# G32M3101 register map
File version: 1.0
CPU: CM0+ r0p1, little endian, MPU, no FPU, 2 interrupt priority bits
Registers are 32-bit, read-write, reset 0x0 unless marked. A register's access mark holds for its fields unless they carry their own. Offsets are from the block's base; [hi:lo] are bit positions; {n}, {i} and the like mark numbered series.

## GTMR — General purpose timer
Base 0x40001000
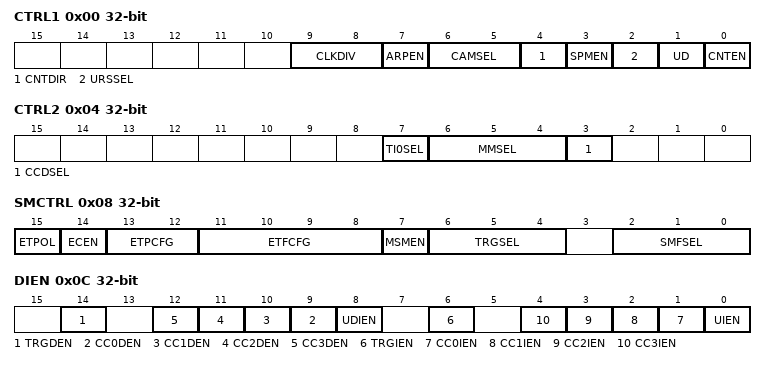
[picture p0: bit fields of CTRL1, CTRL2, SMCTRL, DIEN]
0x00 CTRL1 — control register 1
  [9:8] CLKDIV — Clock division
  [7] ARPEN — Auto-reload preload enable
  [6:5] CAMSEL — Center-aligned mode selection
  [4] CNTDIR — Direction
  [3] SPMEN — One-pulse mode
  [2] URSSEL — Update request source
  [1] UD — Update disable
  [0] CNTEN — Counter enable
0x04 CTRL2 — control register 2
  [7] TI0SEL — TI0 selection
  [6:4] MMSEL — Master mode selection
  [3] CCDSEL — Capture/compare DMA selection
0x08 SMCTRL — slave mode control register
  [15] ETPOL — External trigger polarity
  [14] ECEN — External clock enable
  [13:12] ETPCFG — External trigger prescaler
  [11:8] ETFCFG — External trigger filter
  [7] MSMEN — Master/Slave mode
  [6:4] TRGSEL — Trigger selection
  [2:0] SMFSEL — Slave mode selection
0x0C DIEN — DMA/Interrupt enable register
  [14] TRGDEN — Trigger DMA request enable
  [n+9] CC{n}DEN (n=0..3) — Capture/Compare {n} DMA request enable
  [8] UDIEN — Update DMA request enable
  [6] TRGIEN — Trigger interrupt enable
  [n+1] CC{n}IEN (n=0..3) — Capture/Compare {n} interrupt enable
  [0] UIEN — Update interrupt enable
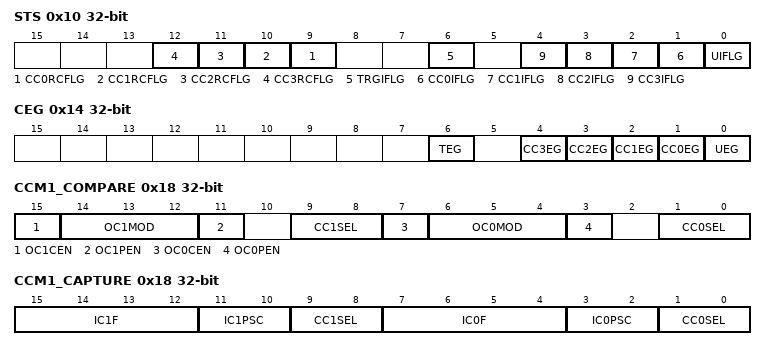
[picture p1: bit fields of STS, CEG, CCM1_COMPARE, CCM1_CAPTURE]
0x10 STS — status register
  [n+9] CC{n}RCFLG (n=0..3) — Capture/Compare {n} overcapture flag
  [6] TRGIFLG — Trigger interrupt flag
  [n+1] CC{n}IFLG (n=0..3) — Capture/compare {n} interrupt flag
  [0] UIFLG — Update interrupt flag
0x14 CEG wo — event generation register
  [6] TEG — Trigger generation
  [n+1] CC{n}EG (n=0..3) — Capture/compare {n} generation
  [0] UEG — Update generation
0x18 CCM1_COMPARE — capture/compare mode register 1 (output mode)
  [15] OC1CEN — Output Compare 1 clear enable
  [14:12] OC1MOD — Output Compare 1 mode
  [11] OC1PEN — Output Compare 1 preload enable
  [9:8] CC1SEL — Capture/Compare 1 selection
  [7] OC0CEN — Output Compare 0 clear enable
  [6:4] OC0MOD — Output Compare 0 mode
  [3] OC0PEN — Output Compare 0 preload enable
  [1:0] CC0SEL — Capture/Compare 0 selection
0x18 CCM1_CAPTURE (alternate view of CCM1_COMPARE) — capture/compare mode register 1 (input mode)
  [15:12] IC1F — Input capture 1 filter
  [11:10] IC1PSC — Input capture 1 prescaler
  [9:8] CC1SEL — Capture/Compare 1 selection
  [7:4] IC0F — Input capture 0 filter
  [3:2] IC0PSC — Input capture 0 prescaler
  [1:0] CC0SEL — Capture/Compare 0 selection
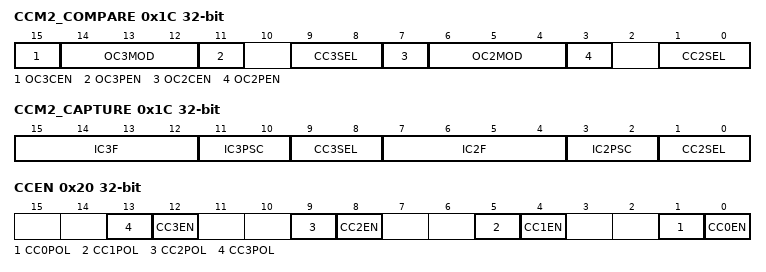
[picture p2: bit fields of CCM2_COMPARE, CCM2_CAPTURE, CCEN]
0x1C CCM2_COMPARE — capture/compare mode register 2 (output mode)
  [15] OC3CEN — Output compare 3 clear enable
  [14:12] OC3MOD — Output compare 3 mode
  [11] OC3PEN — Output compare 3 preload enable
  [9:8] CC3SEL — Capture/Compare 3 selection
  [7] OC2CEN — Output compare 2 clear enable
  [6:4] OC2MOD — Output compare 2 mode
  [3] OC2PEN — Output compare 2 preload enable
  [1:0] CC2SEL — Capture/Compare 2 selection
0x1C CCM2_CAPTURE (alternate view of CCM2_COMPARE) — capture/compare mode register 2 (input mode)
  [15:12] IC3F — Input capture 3 filter
  [11:10] IC3PSC — Input capture 3 prescaler
  [9:8] CC3SEL — Capture/compare 3 selection
  [7:4] IC2F — Input capture 2 filter
  [3:2] IC2PSC — Input capture 2 prescaler
  [1:0] CC2SEL — Capture/compare 2 selection
0x20 CCEN — capture/compare enable register
  [4n+1] CC{n}POL (n=0..3) — Capture/Compare {n} output Polarity
  [4n] CC{n}EN (n=0..3) — Capture/Compare {n} output enable
0x24 CNT — counter
  [31:0] CNT — Counter Value
0x28 PSC — prescaler
  [15:0] PSC — Prescaler value
0x2C AUTORLD — auto-reload register
  [31:0] AUTORLD — Auto Reload Value
0x34 CC0 — capture/compare register 0
  [31:0] CC0 — Capture/Compare 0 value
0x38 CC1 — capture/compare register 1
  [15:0] CC1 — Capture/Compare 1 value
0x3C CC2 — capture/compare register 2
  [31:0] CC2 — Capture/Compare 2 value
0x40 CC3 — capture/compare register 3
  [31:0] CC3 — Capture/Compare 3 value
